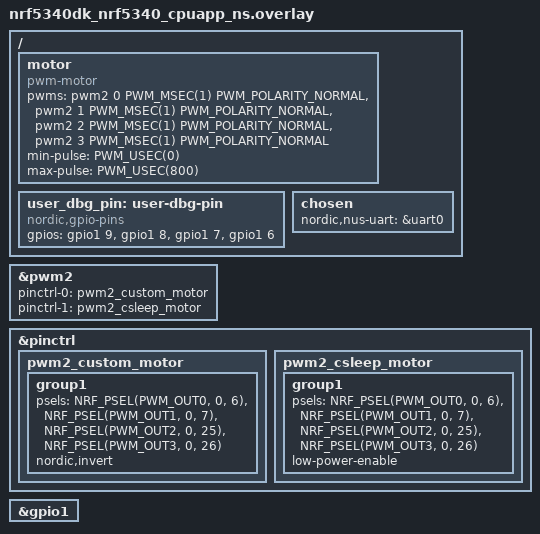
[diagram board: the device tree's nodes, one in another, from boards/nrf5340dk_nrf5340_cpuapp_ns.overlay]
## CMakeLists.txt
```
#
# Copyright (c) 2018 Nordic Semiconductor
#
# SPDX-License-Identifier: LicenseRef-Nordic-5-Clause
#
cmake_minimum_required(VERSION 3.20.0)

find_package(Zephyr REQUIRED HINTS $ENV{ZEPHYR_BASE})
project(RC_Car)

# NORDIC SDK APP START
target_sources(app PRIVATE
  src/main.c
)

# Include UART ASYNC API adapter
target_sources_ifdef(CONFIG_BT_NUS_UART_ASYNC_ADAPTER app PRIVATE
  src/uart_async_adapter.c
)

# NORDIC SDK APP END

zephyr_library_include_directories(.)
```

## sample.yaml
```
sample:
  description: Bluetooth Low Energy UART service sample
  name: BLE UART service
tests:
  sample.bluetooth.peripheral_uart:
    build_only: true
    platform_allow: nrf52dk_nrf52832 nrf52833dk_nrf52833 nrf52840dk_nrf52840
      nrf5340dk_nrf5340_cpuapp nrf5340dk_nrf5340_cpuapp_ns thingy53_nrf5340_cpuapp
      thingy53_nrf5340_cpuapp_ns nrf21540dk_nrf52840
    integration_platforms:
      - nrf52dk_nrf52832
      - nrf52833dk_nrf52833
      - nrf52840dk_nrf52840
      - nrf5340dk_nrf5340_cpuapp
      - nrf5340dk_nrf5340_cpuapp_ns
      - thingy53_nrf5340_cpuapp
      - thingy53_nrf5340_cpuapp_ns
      - nrf21540dk_nrf52840
    tags: bluetooth ci_build
  sample.bluetooth.peripheral_uart.sysbuild:
    build_only: true
    sysbuild: true
    platform_allow: nrf52840dk_nrf52840 nrf5340dk_nrf5340_cpuapp
      nrf5340dk_nrf5340_cpuapp_ns
    integration_platforms:
      - nrf52840dk_nrf52840
      - nrf5340dk_nrf5340_cpuapp
      - nrf5340dk_nrf5340_cpuapp_ns
    tags: bluetooth ci_build sysbuild
  sample.bluetooth.peripheral_uart_cdc:
    build_only: true
    extra_args: OVERLAY_CONFIG=prj_cdc.conf DTC_OVERLAY_FILE="usb.overlay"
    integration_platforms:
      - nrf52840dk_nrf52840
      - nrf52833dk_nrf52833
    platform_allow: nrf52840dk_nrf52840 nrf52833dk_nrf52833
    tags: bluetooth ci_build
  sample.bluetooth.peripheral_uart_minimal:
    build_only: true
    extra_args: OVERLAY_CONFIG=prj_minimal.conf
    integration_platforms:
      - nrf52dk_nrf52810
      - nrf52840dk_nrf52811
      - nrf52833dk_nrf52820
    platform_allow: nrf52dk_nrf52810 nrf52840dk_nrf52811 nrf52833dk_nrf52820
    tags: bluetooth ci_build
  sample.bluetooth.peripheral_uart_ble_rpc:
    build_only: true
    extra_configs:
      - CONFIG_BT_RPC_STACK=y
    integration_platforms:
      - nrf5340dk_nrf5340_cpuapp
    platform_allow: nrf5340dk_nrf5340_cpuapp
    tags: bluetooth ci_build
  sample.bluetooth.peripheral_uart.security_disabled:
    build_only: true
    platform_allow: nrf52dk_nrf52832 nrf52833dk_nrf52833 nrf52840dk_nrf52840
      nrf5340dk_nrf5340_cpuapp nrf5340dk_nrf5340_cpuapp_ns thingy53_nrf5340_cpuapp
      thingy53_nrf5340_cpuapp_ns nrf21540dk_nrf52840
    integration_platforms:
      - nrf52840dk_nrf52840
    tags: bluetooth ci_build
    extra_configs:
      - CONFIG_BT_NUS_SECURITY_ENABLED=n
```

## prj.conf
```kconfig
#
# Copyright (c) 2018 Nordic Semiconductor
#
# SPDX-License-Identifier: LicenseRef-Nordic-5-Clause
#

# Enable the UART driver
CONFIG_UART_ASYNC_API=y
CONFIG_NRFX_UARTE0=y
CONFIG_SERIAL=y

CONFIG_GPIO=y

# Make sure printk is printing to the UART console
CONFIG_CONSOLE=y
CONFIG_UART_CONSOLE=y

CONFIG_HEAP_MEM_POOL_SIZE=2048

CONFIG_BT=y
CONFIG_BT_PERIPHERAL=y
CONFIG_BT_DEVICE_NAME="Nordic_UART_Service"
CONFIG_BT_MAX_CONN=1
CONFIG_BT_MAX_PAIRED=1

# Enable the NUS service
CONFIG_BT_NUS=y

# Enable bonding
CONFIG_BT_SETTINGS=y
CONFIG_FLASH=y
CONFIG_FLASH_PAGE_LAYOUT=y
CONFIG_FLASH_MAP=y
CONFIG_NVS=y
CONFIG_SETTINGS=y

# Enable DK LED and Buttons library
CONFIG_DK_LIBRARY=y

# This example requires more stack
CONFIG_MAIN_STACK_SIZE=1152
CONFIG_SYSTEM_WORKQUEUE_STACK_SIZE=2048

# Config logger
CONFIG_LOG=y
CONFIG_USE_SEGGER_RTT=y
CONFIG_LOG_BACKEND_RTT=y
CONFIG_LOG_BACKEND_UART=n
CONFIG_LOG_PRINTK=n

CONFIG_ASSERT=y

CONFIG_PWM=y
CONFIG_LED=y
CONFIG_LED_PWM=y
```

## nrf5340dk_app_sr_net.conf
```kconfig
#
# Copyright (c) 2022 Nordic Semiconductor
#
# SPDX-License-Identifier: LicenseRef-Nordic-5-Clause
#

CONFIG_BOOTLOADER_MCUBOOT=y
CONFIG_NRF53_UPGRADE_NETWORK_CORE=y
CONFIG_ADD_MCUBOOT_MEDIATE_SIM_FLASH_DTS=y
```

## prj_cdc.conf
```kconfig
#
# Copyright (c) 2021 Nordic Semiconductor
#
# SPDX-License-Identifier: LicenseRef-Nordic-5-Clause
#

# Enable the UART driver
CONFIG_UART_LINE_CTRL=y
CONFIG_UART_INTERRUPT_DRIVEN=y
CONFIG_BT_NUS_UART_ASYNC_ADAPTER=y
CONFIG_USB_DEVICE_STACK=y
CONFIG_USB_DEVICE_REMOTE_WAKEUP=n
CONFIG_USB_CDC_ACM=y
CONFIG_USB_CDC_ACM_LOG_LEVEL_OFF=y

# Disable the UARTE0 enabled in default project configuration
CONFIG_NRFX_UARTE0=n
CONFIG_UART_NRFX=n
```

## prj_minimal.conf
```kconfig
#
# Copyright (c) 2021 Nordic Semiconductor
#
# SPDX-License-Identifier: LicenseRef-Nordic-5-Clause
#

# Enable the UART driver
CONFIG_UART_ASYNC_API=y
CONFIG_NRFX_UARTE0=y
CONFIG_SERIAL=y

CONFIG_HEAP_MEM_POOL_SIZE=2048

CONFIG_BT=y
CONFIG_BT_PERIPHERAL=y
CONFIG_BT_DEVICE_NAME="Nordic_UART_Service"
CONFIG_BT_DEVICE_APPEARANCE=833
CONFIG_BT_MAX_CONN=1
CONFIG_BT_MAX_PAIRED=1

# Enable the NUS service
CONFIG_BT_NUS=y

# Enable bonding
CONFIG_BT_SETTINGS=y
CONFIG_FLASH=y
CONFIG_FLASH_PAGE_LAYOUT=y
CONFIG_FLASH_MAP=y
CONFIG_NVS=y
CONFIG_SETTINGS=y

# Enable DK LED and Buttons library
CONFIG_DK_LIBRARY=y

# Drivers and peripherals
CONFIG_I2C=n
CONFIG_WATCHDOG=n
CONFIG_SPI=n
CONFIG_GPIO=n

# Power management

# Interrupts
CONFIG_DYNAMIC_INTERRUPTS=n
CONFIG_IRQ_OFFLOAD=n

# Memory protection
CONFIG_THREAD_STACK_INFO=n
CONFIG_THREAD_CUSTOM_DATA=n
CONFIG_FPU=n

# Boot
CONFIG_BOOT_BANNER=n
CONFIG_BOOT_DELAY=0

# Console
CONFIG_CONSOLE=n
CONFIG_UART_CONSOLE=n
CONFIG_STDOUT_CONSOLE=n
CONFIG_PRINTK=n
CONFIG_EARLY_CONSOLE=n

# Build
CONFIG_SIZE_OPTIMIZATIONS=y

# ARM
CONFIG_ARM_MPU=n

# In order to correctly tune the stack sizes for the threads the following
# Configurations can enabled to print the current use:
#CONFIG_THREAD_NAME=y
#CONFIG_THREAD_ANALYZER=y
#CONFIG_THREAD_ANALYZER_AUTO=y
#CONFIG_THREAD_ANALYZER_RUN_UNLOCKED=y
#CONFIG_THREAD_ANALYZER_USE_PRINTK=y
#CONFIG_CONSOLE=y
#CONFIG_UART_CONSOLE=y
#CONFIG_SERIAL=y
#CONFIG_PRINTK=y

# Example output of thread analyzer
#SDC RX              : unused 800 usage 224 / 1024 (21 %)
#BT ECC              : unused 216 usage 888 / 1104 (80 %)
#BT RX               : unused 1736 usage 464 / 2200 (21 %)
#BT TX               : unused 1008 usage 528 / 1536 (34 %)
#ble_write_thread_id : unused 688 usage 336 / 1024 (32 %)
#sysworkq            : unused 1912 usage 136 / 2048 (6 %)
#MPSL signal         : unused 928 usage 96 / 1024 (9 %)
#idle 00             : unused 224 usage 96 / 320 (30 %)
#main                : unused 568 usage 456 / 1024 (44 %)
CONFIG_BT_RX_STACK_SIZE=1024
CONFIG_BT_HCI_TX_STACK_SIZE_WITH_PROMPT=y
CONFIG_BT_HCI_TX_STACK_SIZE=640
CONFIG_SYSTEM_WORKQUEUE_STACK_SIZE=1536
CONFIG_MPSL_WORK_STACK_SIZE=256
CONFIG_MAIN_STACK_SIZE=864
CONFIG_IDLE_STACK_SIZE=128
CONFIG_ISR_STACK_SIZE=1024
CONFIG_BT_NUS_THREAD_STACK_SIZE=512

# Disable features not needed
CONFIG_TIMESLICING=n
CONFIG_MINIMAL_LIBC_MALLOC=n
CONFIG_LOG=n
CONFIG_ASSERT=n

# Disable Bluetooth features not needed
CONFIG_BT_DEBUG_NONE=y
CONFIG_BT_ASSERT=n
CONFIG_BT_DATA_LEN_UPDATE=n
CONFIG_BT_PHY_UPDATE=n
CONFIG_BT_GATT_CACHING=n
CONFIG_BT_GATT_SERVICE_CHANGED=n
CONFIG_BT_GAP_PERIPHERAL_PREF_PARAMS=n
CONFIG_BT_SETTINGS_CCC_LAZY_LOADING=y
CONFIG_BT_HCI_VS_EXT=n

# Disable Bluetooth controller features not needed
CONFIG_BT_CTLR_PRIVACY=n
CONFIG_BT_CTLR_PHY_2M=n

# Reduce Bluetooth buffers
CONFIG_BT_BUF_EVT_DISCARDABLE_COUNT=1
CONFIG_BT_BUF_EVT_DISCARDABLE_SIZE=43
CONFIG_BT_BUF_EVT_RX_COUNT=2

CONFIG_BT_CONN_TX_MAX=2
CONFIG_BT_L2CAP_TX_BUF_COUNT=2
CONFIG_BT_BUF_ACL_TX_COUNT=3
CONFIG_BT_BUF_ACL_TX_SIZE=27
```

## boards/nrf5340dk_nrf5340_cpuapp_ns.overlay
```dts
/******************** NEW CODE *****************************/
/ {
    motor: motor {
        compatible = "pwm-motor";
        pwms = <&pwm2 0 PWM_MSEC(1) PWM_POLARITY_NORMAL>,
               <&pwm2 1 PWM_MSEC(1) PWM_POLARITY_NORMAL>, // Trying to create a second pwm channel
               <&pwm2 2 PWM_MSEC(1) PWM_POLARITY_NORMAL>,
               <&pwm2 3 PWM_MSEC(1) PWM_POLARITY_NORMAL>;
        min-pulse = <PWM_USEC(0)>;
        max-pulse = <PWM_USEC(800)>; // 1000 for 100% pwm
    };
};


&pwm2 {
    status = "okay";
    pinctrl-0 = <&pwm2_custom_motor>;
    pinctrl-1 = <&pwm2_csleep_motor>;
    pinctrl-names = "default", "sleep";
};

&pinctrl {
    pwm2_custom_motor: pwm2_custom_motor {
        group1 {
            psels = <NRF_PSEL(PWM_OUT0, 0, 6)>,
                    <NRF_PSEL(PWM_OUT1, 0, 7)>, // Trying to create a second pwm channel
                    <NRF_PSEL(PWM_OUT2, 0, 25)>,
                    <NRF_PSEL(PWM_OUT3, 0, 26)>;
            nordic,invert;
        };
    };

    pwm2_csleep_motor: pwm2_csleep_motor {
        group1 {
            psels = <NRF_PSEL(PWM_OUT0, 0, 6)>,
                    <NRF_PSEL(PWM_OUT1, 0, 7)>, // Trying to create a second pwm channel
                    <NRF_PSEL(PWM_OUT2, 0, 25)>,
                    <NRF_PSEL(PWM_OUT3, 0, 26)>;
            low-power-enable;
        };
    };
};


/*Trying to get GPIO pins working through this overlay file */
/ {
    user_dbg_pin: user-dbg-pin {
            compatible = "nordic,gpio-pins";
            gpios = <&gpio1 9 GPIO_ACTIVE_HIGH>,
                    <&gpio1 8 GPIO_ACTIVE_HIGH>, // Trying to create a second GPIO pin to use
                    <&gpio1 7 GPIO_ACTIVE_HIGH>,
                    <&gpio1 6 GPIO_ACTIVE_HIGH>;
            status = "okay";
    };
};

&gpio1 {
    status = "okay";
};

/ {
	chosen {
		nordic,nus-uart = &uart0;
	};
};
```

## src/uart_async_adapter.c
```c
/*
 * Copyright (c) 2021 Nordic Semiconductor ASA
 *
 * SPDX-License-Identifier: LicenseRef-Nordic-5-Clause
 */

/** @file
 *  @brief UART asynchronous API adapter implementation
 */
#include "uart_async_adapter.h"
#include <zephyr/drivers/uart.h>
#include <zephyr/sys/__assert.h>

#include <zephyr/logging/log.h>
LOG_MODULE_REGISTER(uart_async_adapter);


#if !IS_ENABLED(CONFIG_UART_ASYNC_API)
#error "This adapter requires UART ASYNC API to be enabled"
#endif

#if !IS_ENABLED(CONFIG_UART_INTERRUPT_DRIVEN)
#error "The adapter requires UART INTERRUPT API to be enabled"
#endif


/**
 * @brief Access the data inside device
 *
 * This function gets the pointer to the user data inside device
 *
 * @param dev Device to get adapter data
 * @return Pointer to device data
 */
static struct uart_async_adapter_data *access_dev_data(const struct device *dev)
{
	__ASSERT_NO_MSG(dev);
	__ASSERT_NO_MSG(dev->data);
	return (struct uart_async_adapter_data *)(dev->data);
}

/**
 * @brief Call the sync callback function
 *
 * @param dev UART device structure.
 * @param evt Pointer to uart_event structure.
 */
static void user_callback(const struct device *dev, struct uart_event *evt)
{
	struct uart_async_adapter_data *data = access_dev_data(dev);

	if (data->user_callback) {
		data->user_callback(dev, evt, data->user_data);
	}
}

static int callback_set(const struct device *dev, uart_callback_t callback, void *user_data)
{
	struct uart_async_adapter_data *data = access_dev_data(dev);

	data->user_callback = callback;
	data->user_data = user_data;

	return 0;
}

static inline void notify_rx_buffer(const struct device *dev)
{
	struct uart_event event = {UART_RX_RDY};
	struct uart_async_adapter_data *data = access_dev_data(dev);
	bool notify = false;

	k_spinlock_key_t key = k_spin_lock(&(data->lock));

	if (data->rx.buf) {

		__ASSERT_NO_MSG(data->rx.curr_buf >= data->rx.buf);
		__ASSERT_NO_MSG(data->rx.curr_buf >= data->rx.last_notify_buf);
		if (data->rx.curr_buf > data->rx.last_notify_buf) {

			event.data.rx.buf = data->rx.buf;
			event.data.rx.len = data->rx.curr_buf - data->rx.last_notify_buf;
			event.data.rx.offset = data->rx.last_notify_buf - data->rx.buf;
			data->rx.last_notify_buf = data->rx.curr_buf;
			notify = true;
		}
	}

	k_spin_unlock(&(data->lock), key);

	if (notify) {
		LOG_DBG("Notification: UART_RX_RDY (0x%x + %d, size: %d)",
			(unsigned int)event.data.rx.buf, event.data.rx.offset, event.data.rx.len);
		user_callback(dev, &event);
	}
}

static inline void notify_rx_buffer_release(const struct device *dev, uint8_t *buf)
{
	struct uart_event event = {
		.type = UART_RX_BUF_RELEASED,
		.data.rx_buf.buf = buf
	};
	LOG_DBG("Notification: UART_RX_BUF_RELEASED");
	user_callback(dev, &event);
}

static inline void notify_rx_buffer_req(const struct device *dev)
{
	struct uart_event event = {
		.type = UART_RX_BUF_REQUEST,
	};
	LOG_DBG("Notification: UART_RX_BUF_REQUEST");
	user_callback(dev, &event);
}

static inline void switch_rx_buffer(const struct device *dev, bool request_new)
{
	struct uart_async_adapter_data *data = access_dev_data(dev);
	uint8_t *old_buf;

	k_spinlock_key_t key = k_spin_lock(&(data->lock));

	old_buf = data->rx.buf;
	data->rx.buf = data->rx.next_buf;
	data->rx.curr_buf = data->rx.next_buf;
	data->rx.last_notify_buf = data->rx.next_buf;
	data->rx.size_left = data->rx.next_buf_len;
	data->rx.next_buf = NULL;
	data->rx.next_buf_len = 0;

	k_spin_unlock(&(data->lock), key);

	if (old_buf) {
		notify_rx_buffer_release(dev, old_buf);
	}
	if (request_new) {
		notify_rx_buffer_req(dev);
	}
}

static int tx(const struct device *dev, const uint8_t *buf, size_t len, int32_t timeout)
{
	int ret = 0;
	struct uart_async_adapter_data *data = access_dev_data(dev);
	bool tx_send = false;

	LOG_DBG("%s(%s, 0x%x, %u, %d)", __func__, dev->name, (unsigned int)buf, len, timeout);

	k_spinlock_key_t key = k_spin_lock(&(data->lock));

	if (!len) {
		LOG_DBG("%s: no data", __func__);
	} else if (data->tx.buf) {
		ret = -EBUSY;
		LOG_DBG("%s: busy", __func__);
	} else {
		data->tx.buf = buf;
		data->tx.curr_buf = buf;
		data->tx.size_left = len;
		data->tx.enabled = true;
		tx_send = true;
		LOG_DBG("%s: sending", __func__);
	}

	k_spin_unlock(&(data->lock), key);

	if (tx_send) {
		uart_irq_tx_enable(data->target);
	}
	if (tx_send && timeout != SYS_FOREVER_US) {
		k_timer_start(&data->tx.timeout_timer, K_USEC(timeout), K_NO_WAIT);
	}
	return ret;
}

static int tx_abort(const struct device *dev)
{
	int ret = 0;
	struct uart_event event = {UART_TX_ABORTED};
	struct uart_async_adapter_data *data = access_dev_data(dev);

	data->tx.enabled = false;
	k_timer_stop(&data->tx.timeout_timer);
	uart_irq_tx_disable(data->target);

	k_spinlock_key_t key = k_spin_lock(&(data->lock));

	if (data->tx.buf == NULL) {
		ret = -EFAULT;
	} else {
		/* Set the event data */
		event.data.tx.buf = data->tx.buf;
		event.data.tx.len = data->tx.curr_buf - data->tx.buf;
		/* Clear any pending tx */
		data->tx.buf = NULL;
		data->tx.curr_buf = NULL;
		data->tx.size_left = 0;
	}

	k_spin_unlock(&(data->lock), key);

	if (!ret) {
		user_callback(dev, &event);
	}
	return ret;
}


static int rx_enable(const struct device *dev, uint8_t *buf, size_t len, int32_t timeout)
{
	int ret = 0;
	struct uart_async_adapter_data *data = access_dev_data(dev);

	k_spinlock_key_t key = k_spin_lock(&(data->lock));

	if (data->rx.next_buf || data->rx.buf) {
		ret = -EBUSY;
	}
	data->rx.buf = NULL;
	data->rx.curr_buf = NULL;
	data->rx.size_left = 0;
	data->rx.next_buf = buf;
	data->rx.next_buf_len = len;
	data->rx.timeout = timeout;
	data->rx.enabled = true;

	k_spin_unlock(&(data->lock), key);

	uart_irq_rx_enable(data->target);
	uart_irq_err_enable(data->target);
	return ret;
}

static int rx_buf_rsp(const struct device *dev, uint8_t *buf, size_t len)
{
	int ret = 0;
	struct uart_async_adapter_data *data = access_dev_data(dev);

	k_spinlock_key_t key = k_spin_lock(&(data->lock));

	if (data->rx.next_buf) {
		ret = -EBUSY;
	} else {
		__ASSERT_NO_MSG(!data->rx.next_buf_len);
		data->rx.next_buf = buf;
		data->rx.next_buf_len = len;
	}

	k_spin_unlock(&(data->lock), key);

	return ret;
}

static int rx_disable(const struct device *dev)
{
	int ret = 0;
	struct uart_async_adapter_data *data = access_dev_data(dev);
	struct uart_event event_disabled = {UART_RX_DISABLED};

	data->rx.enabled = false;
	uart_irq_rx_disable(data->target);
	uart_irq_err_disable(data->target);
	while (data->rx.buf) {
		switch_rx_buffer(dev, false);
	}

	user_callback(dev, &event_disabled);

	return ret;
}

/* Basic interface */

static int poll_in(const struct device *dev, unsigned char *p_char)
{
	__ASSERT_NO_MSG(dev);

	const struct uart_async_adapter_data *data = dev->data;

	__ASSERT_NO_MSG(data);
	__ASSERT_NO_MSG(data->target);

	return uart_poll_in(data->target, p_char);
}

static void poll_out(const struct device *dev, unsigned char out_char)
{
	__ASSERT_NO_MSG(dev);

	const struct uart_async_adapter_data *data = dev->data;

	__ASSERT_NO_MSG(data);
	__ASSERT_NO_MSG(data->target);

	uart_poll_out(data->target, out_char);
}

static int err_check(const struct device *dev)
{
	__ASSERT_NO_MSG(dev);

	const struct uart_async_adapter_data *data = dev->data;

	__ASSERT_NO_MSG(data);
	__ASSERT_NO_MSG(data->target);

	return uart_err_check(data->target);
}

#ifdef CONFIG_UART_USE_RUNTIME_CONFIGURE
static int configure(const struct device *dev, const struct uart_config *cfg)
{
	__ASSERT_NO_MSG(dev);

	const struct uart_async_adapter_data *data = dev->data;

	__ASSERT_NO_MSG(data);
	__ASSERT_NO_MSG(data->target);

	return uart_configure(data->target, cfg);
}

static int config_get(const struct device *dev, struct uart_config *cfg)
{
	__ASSERT_NO_MSG(dev);

	const struct uart_async_adapter_data *data = dev->data;

	__ASSERT_NO_MSG(data);
	__ASSERT_NO_MSG(data->target);

	return uart_config_get(data->target, cfg);
}
#endif /* CONFIG_UART_USE_RUNTIME_CONFIGURE */


#ifdef CONFIG_UART_LINE_CTRL

static int line_ctrl_set(const struct device *dev, uint32_t ctrl, uint32_t val)
{
	__ASSERT_NO_MSG(dev);

	const struct uart_async_adapter_data *data = dev->data;

	__ASSERT_NO_MSG(data);
	__ASSERT_NO_MSG(data->target);

	return uart_line_ctrl_set(data->target, ctrl, val);
}

static int line_ctrl_get(const struct device *dev, uint32_t ctrl, uint32_t *val)
{
	__ASSERT_NO_MSG(dev);

	const struct uart_async_adapter_data *data = dev->data;

	__ASSERT_NO_MSG(data);
	__ASSERT_NO_MSG(data->target);

	return uart_line_ctrl_get(data->target, ctrl, val);
}

#endif /* CONFIG_UART_LINE_CTRL */

#ifdef CONFIG_UART_DRV_CMD

static int drv_cmd(const struct device *dev, uint32_t cmd, uint32_t p)
{
	__ASSERT_NO_MSG(dev);

	const struct uart_async_adapter_data *data = dev->data;

	__ASSERT_NO_MSG(data);
	__ASSERT_NO_MSG(data->target);

	return uart_drv_cmd(data->target, cmd, p);
}

#endif /* CONFIG_UART_DRV_CMD */

static inline void on_tx_ready(const struct device *dev, struct uart_async_adapter_data *data)
{
	k_spinlock_key_t key = k_spin_lock(&(data->lock));

	LOG_DBG("%s: Enter(%s) (left: %u)", __func__, dev->name, data->tx.size_left);
	if (data->tx.size_left) {
		__ASSERT_NO_MSG(data->tx.curr_buf);
		int ret;

		ret = uart_fifo_fill(data->target, data->tx.curr_buf, data->tx.size_left);
		LOG_DBG("Pushed %d characters", ret);
		if (ret <= 0) {
			LOG_ERR("Unexpected fifo fill err: %d", ret);
		} else {
			data->tx.curr_buf += ret;
			data->tx.size_left -= ret;
		}
	}

	k_spin_unlock(&(data->lock), key);

	LOG_DBG("%s: Exit", __func__);
}

static inline void on_tx_complete(const struct device *dev, struct uart_async_adapter_data *data)
{
	LOG_DBG("%s: Enter(%s)", __func__, dev->name);
	if (!data->tx.size_left) {
		struct uart_event event = {UART_TX_DONE};

		data->tx.enabled = false;
		uart_irq_tx_disable(data->target);

		k_spinlock_key_t key = k_spin_lock(&(data->lock));

		if (data->tx.buf) {
			__ASSERT_NO_MSG(data->tx.curr_buf);
			__ASSERT_NO_MSG(data->tx.curr_buf >= data->tx.buf);
			/* Transfer really finished */
			event.data.tx.buf = data->tx.buf;
			event.data.tx.len = data->tx.curr_buf - data->tx.buf;
			/* Clear any pending tx */
			data->tx.buf = NULL;
			data->tx.curr_buf = NULL;
			data->tx.size_left = 0;
		}

		k_spin_unlock(&(data->lock), key);

		if (event.data.tx.buf) {
			LOG_DBG("Notification: UART_TX_DONE (0x%x, size: %d)",
				(unsigned int)event.data.tx.buf, event.data.tx.len);
			user_callback(dev, &event);
		} else {
			LOG_ERR("TX buffer NULL on tx complete");
		}
	}
	LOG_DBG("%s: Exit", __func__);
}

static inline void on_rx_ready(const struct device *dev, struct uart_async_adapter_data *data)
{
	int ret;
	bool notify_now = false;

	LOG_DBG("%s: Enter (%s)", __func__, dev->name);
	if (data->rx.timeout != SYS_FOREVER_US) {
		k_timer_start(&data->rx.timeout_timer, K_USEC(data->rx.timeout), K_NO_WAIT);
	}
	do {
		k_spinlock_key_t key = k_spin_lock(&(data->lock));

		if (!data->rx.size_left) {
			notify_now = false;

			k_spin_unlock(&(data->lock), key);

			notify_rx_buffer(dev);
			switch_rx_buffer(dev, true);

			key = k_spin_lock(&(data->lock));
		}
		if (!data->rx.size_left) {
			/* Data received without buffer - dropping */
			uint8_t dummy;
			size_t cnt = 0;

			do {
				ret = uart_fifo_read(data->target, &dummy, 1);
				if (ret < 0) {
					LOG_ERR("Unexpected error on FIFO dropping: %d", ret);
					ret = 0;
				}
				cnt += ret;
			} while (ret);
			LOG_ERR("Data received without buffer prepared, dropped %d bytes", cnt);
		} else {
			ret = uart_fifo_read(data->target, data->rx.curr_buf, data->rx.size_left);
			LOG_DBG("Received %d characters", ret);
			if (ret < 0) {
				LOG_ERR("Unexpected error on FIFO read: %d", ret);
				ret = 0;
			}
			__ASSERT_NO_MSG(data->rx.size_left >= ret);
			data->rx.curr_buf += ret;
			data->rx.size_left -= ret;
			if (data->rx.timeout == 0) {
				notify_now = true;
			}
		}

		k_spin_unlock(&(data->lock), key);

	} while (ret);
	if (notify_now) {
		notify_rx_buffer(dev);
	}
	LOG_DBG("%s: Exit", __func__);
}

static inline void on_error(const struct device *dev,
			    struct uart_async_adapter_data *data,
			    int rx_err)
{
	struct uart_event event = {
		.type = UART_RX_STOPPED,
		.data.rx_stop.reason = rx_err
	};

	LOG_DBG("%s: Enter(%s)", __func__, dev->name);
	rx_disable(data->target);
	user_callback(dev, &event);
	LOG_DBG("%s: Exit", __func__);
}

static void uart_irq_handler(const struct device *target_dev, void *context)
{
	const struct device *dev = context;
	struct uart_async_adapter_data *data = access_dev_data(dev);

	__ASSERT(target_dev == data->target,
		"IRQ handler called with a context that seems uninitialized.");
	LOG_DBG("irq_handler: Enter");
	if (uart_irq_update(target_dev) && uart_irq_is_pending(target_dev)) {
		if (data->tx.enabled && uart_irq_tx_ready(target_dev)) {
			on_tx_ready(dev, data);
		}
		if (data->tx.enabled && uart_irq_tx_complete(target_dev)) {
			on_tx_complete(dev, data);
		}
		if (data->rx.enabled && uart_irq_rx_ready(target_dev)) {
			on_rx_ready(dev, data);
		}

		/* Check errors only after all the data is received from the device */
		int rx_err = uart_err_check(target_dev);

		if (rx_err < 0) {
			rx_err = 0;
		}
		if (data->rx.enabled && rx_err) {
			on_error(dev, data, rx_err);
		}
	}
	LOG_DBG("irq_handler: Exit");
}

const struct uart_driver_api uart_async_adapter_driver_api = {
	/* Async interface */
	.callback_set = callback_set,
	.tx = tx,
	.tx_abort = tx_abort,
	.rx_enable = rx_enable,
	.rx_buf_rsp = rx_buf_rsp,
	.rx_disable = rx_disable,

	/* Basic functions */
	.poll_in = poll_in,
	.poll_out = poll_out,
	.err_check = err_check,
#ifdef CONFIG_UART_USE_RUNTIME_CONFIGURE
	.configure = configure,
	.config_get = config_get,
#endif

#ifdef CONFIG_UART_LINE_CTRL
	.line_ctrl_set = line_ctrl_set,
	.line_ctrl_get = line_ctrl_get
#endif

#ifdef CONFIG_UART_DRV_CMD
	.drv_cmd = drv_cmd
#endif
};


static void tx_timeout(struct k_timer *timer)
{
	const struct device *dev = k_timer_user_data_get(timer);

	(void)tx_abort(dev);
}

static void rx_timeout(struct k_timer *timer)
{
	const struct device *dev = k_timer_user_data_get(timer);

	notify_rx_buffer(dev);
}

void uart_async_adapter_init(const struct device *dev, const struct device *target)
{
	__ASSERT_NO_MSG(dev);
	__ASSERT_NO_MSG(dev->api);
	__ASSERT(dev->api == &uart_async_adapter_driver_api,
		"This is not uart_async_adapter device");

	struct uart_async_adapter_data *data = access_dev_data(dev);

	data->target = target;
	uart_irq_callback_user_data_set(data->target, uart_irq_handler, (void *)dev);

	k_timer_init(&data->tx.timeout_timer, tx_timeout, NULL);
	k_timer_user_data_set(&data->tx.timeout_timer, (void *)dev);
	k_timer_init(&data->rx.timeout_timer, rx_timeout, NULL);
	k_timer_user_data_set(&data->rx.timeout_timer, (void *)dev);

	dev->state->initialized = true;
}
```
